# RN8XXX_V2 register map
File version: 1.0
Registers are 32-bit, read-write, reset 0x0 unless marked. A register's access mark holds for its fields unless they carry their own. Offsets are from the block's base; [hi:lo] are bit positions; {n}, {i} and the like mark numbered series; 'fields as' and 'values as' point back to an identical list.

## UART0 — UART tranceiver
Base 0x40000000
Same registers: UART1 0x40004000, UART2 0x40008000, UART3 0x4000C000, UART4 0x40018000, UART5 0x4001C000
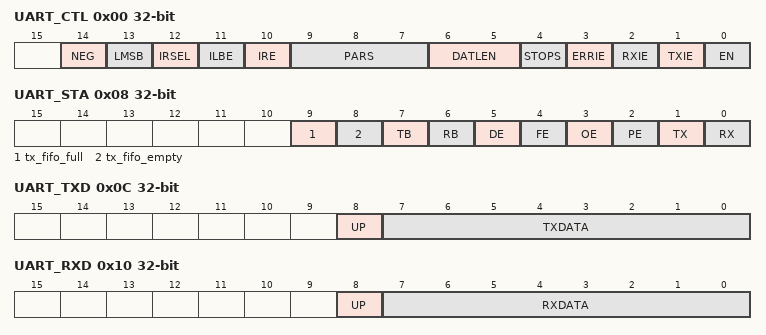
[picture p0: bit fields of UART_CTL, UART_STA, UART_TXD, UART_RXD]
0x00 UART_CTL — UART control register
  [14] NEG — UART transfer bit polarity selection
    0=positive polarity. default driving voltage is high; 1=negative polarity. default driving voltage is low
  [13] LMSB — LSB/MSB transfer mode selection
    0=LSB first transfer mode; 1=MSB first transfer mode
  [12] IRSEL — infra-red modulation polarity selection
    values as NEG
  [11] ILBE — inner loopback enable
    0=disable (inner loopback disabled); 1=enable (inner loopback enabled)
  [10] IRE — infra-red modulation enable
    0=disable (infra-red modulation disabled); 1=enable (infra-red modulation enabled)
  [9:7] PARS — parity selection
    0=no_parity; 1=odd_parity; 2=even_parity; 3=stick_zero_parity (parity always zero); 4=stick_one_parity (parity always one); 5=user_defined_parity1; 6=user_defined_parity2; 7=user_defined_parity3
  [6:5] DATLEN — data length of frame format
    {v}=d{v+5} ({v+5} bits of data field) (v=0..3)
  [4] STOPS — stop bits width selection
    0=stop1 (one stop bit); 1=stop2 (two stop bits)
  [3] ERRIE — error interrupt enable
    0=disable (error interrupt disabled); 1=enable (error interrupt enabled)
  [2] RXIE — receive interrupt enable
    0=disable (receive interrupt disabled); 1=enable (receive interrupt enabled)
  [1] TXIE — transmit interrupt enable
    0=disable (transmit interrupt disabled); 1=enable (transmit interrupt enabled)
  [0] EN — tranceiver enable
    0=disable (transmit and receive engine disabled); 1=enable (transmit and receive engine enabled)
0x04 UART_BAUD — baud rate configuration
  [12:0] CLKDIV — baudrate divisor.baudrate=systemclock/[16*(CLKDIV+1)]
0x08 UART_STA — UART status register.
  [9] tx_fifo_full ro — transmit fifo full flag
    0=not_full (transmit FIFO not full); 1=full (transmit FIFO full(full of outstanding data packet))
  [8] tx_fifo_empty ro — transmit fifo empty flag
    0=not_empty (transmit FIFO not empty (containing outstanding data packet)); 1=empty (transmit FIFO empty (containing no outstanding data packet))
  [7] TB ro — transmitter data flag
    0=not_busy (no packet in transmit); 1=busy (packet in transmitting)
  [6] RB ro — receiver busy flag
    0=not_busy (no receive); 1=busy (packet in receiving)
  [5] DE write-1-clears — data error
    0=not_data_error (no data error found); 1=data_error (pending data error found)
  [4] FE write-1-clears — frame error
    0=not_frame_error (no frame error found); 1=frame_error (pending frame error found)
  [3] OE write-1-clears — overflow error
    0=not_overflow_error (no overflow error found); 1=overflow_error (pending overflow error found)
  [2] PE write-1-clears — parity error
    0=not_parity_error (no parity error found); 1=parity_error (pending parity error found)
  [1] TX write-1-clears — transmit flag
    0=not_tx (packet in transmit or no packet in transmit); 1=tx (packet transmit)
  [0] RX write-1-clears — receive flag
    0=no_rx_pending (no outstanding packet received); 1=rx_pending (packet received)
0x0C UART_TXD — transmitting data
  [8] UP — user-defined parity bit(valid when user-defined parity selected)
  [7:0] TXDATA — Transmitting data
0x10 UART_RXD — received data
  [8] UP ro — parity received
  [7:0] RXDATA ro — Receiving data
0x14 UART_FDIV — baud rate fractional part
  [13:0] FDIV — baudrate fraction. fractional parameter=rounddown((systemclock/(16*baudrate) - rounddown(systemclock/(16*baudrate)))*2^14 + 0.5)
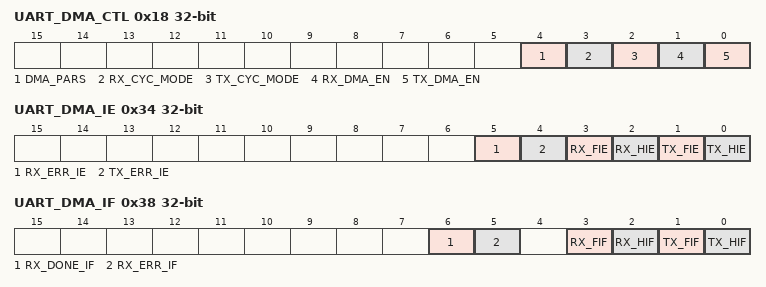
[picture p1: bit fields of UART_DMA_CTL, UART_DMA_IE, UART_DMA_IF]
0x18 UART_DMA_CTL — UART DMA control register
  [4] DMA_PARS — UART DMA parity
  [3] RX_CYC_MODE — UART RX loop mode enable
  [2] TX_CYC_MODE — UART TX loop mode enable
  [1] RX_DMA_EN — UART RX DMA enable
  [0] TX_DMA_EN — UART TX DMA enable
0x1C UART_DMA_TBADR — UART DMA TX base address
  [16:0] DMA_TBADR — DMA TX base address
0x20 UART_DMA_RBADR — UART DMA RX base address
  [16:0] DMA_RBADR — DMA RX base address
0x24 UART_DMA_TLEN — UART DMA TX length
  [16:0] DMA_TLEN — DMA TX length
0x28 UART_DMA_RLEN — UART DMA RX length
  [16:0] DMA_RLEN — DMA RX length
0x2C UART_DMA_TADR — UART DMA TX current address
  [16:0] DMA_TADR ro — DMA TX current address
0x30 UART_DMA_RADR — UART DMA RX current address
  [16:0] DMA_RADR ro — DMA RX current address
0x34 UART_DMA_IE — UART DMA interrupt enable register
  [5] RX_ERR_IE — DMA RX error interrupt
    0=disable (receive error interrupt disabled); 1=enable (receive error interrupt enabled)
  [4] TX_ERR_IE — DMA TX error interrupt
    0=disable (transmit error interrupt disabled); 1=enable (transmit error interrupt enabled)
  [3] RX_FIE — DMA RX full interrupt
    0=disable (receive full interrupt disabled); 1=enable (receive full interrupt enabled)
  [2] RX_HIE — DMA RX half-full interrupt
    0=disable (receive half-full interrupt disabled); 1=enable (receive half-full interrupt enabled)
  [1] TX_FIE — DMA TX empty interrupt
    0=disable (transmit empty interrupt disabled); 1=enable (transmit empty interrupt enabled)
  [0] TX_HIE — DMA TX half-full interrupt
    0=disable (transmit half-full interrupt disabled); 1=enable (transmit half-full interrupt enabled)
0x38 UART_DMA_IF — UART DMA interrupt flag register
  [6] RX_DONE_IF write-1-clears — DMA RX done interrupt flag
    0=no pending (no receive done interrupt); 1=pending (receive done interrupt pending)
  [5] RX_ERR_IF write-1-clears — DMA RX error interrupt flag
    0=no pending (no receive error interrupt); 1=pending (receive error interrupt pending)
  [3] RX_FIF write-1-clears — DMA RX full interrupt flag
    0=no pending (no receive full interrupt); 1=pending (receive full interrupt pending)
  [2] RX_HIF write-1-clears — DMA RX half-full interrupt flag
    0=no pending (no receive half-full interrupt); 1=pending (receive half-full interrupt pending)
  [1] TX_FIF write-1-clears — DMA TX empty interrupt flag
    0=no pending (no transmit empty interrupt); 1=enable (transmit empty interrupt pending)
  [0] TX_HIF write-1-clears — DMA TX half-full interrupt flag
    0=no pending (no TX half-full interrupt); 1=pending (TX half-full interrupt pending)
0x3C UART_DMA_TO — UART DMA Time out
  [3:0] DMA_TO_CNT — DMA time out counter
